# MCXN947_cm33_core0 register map
Vendor: nxp.com; File version: 1.0
CPU: CM33 r2p0, little endian, MPU, FPU, VTOR, 3 interrupt priority bits
Registers are 32-bit, read-write, reset 0x0 unless marked. A register's access mark holds for its fields unless they carry their own. Offsets are from the block's base; [hi:lo] are bit positions; {n}, {i} and the like mark numbered series; 'fields as' and 'values as' point back to an identical list.

## WUU0 — WUU
Base 0x40046000
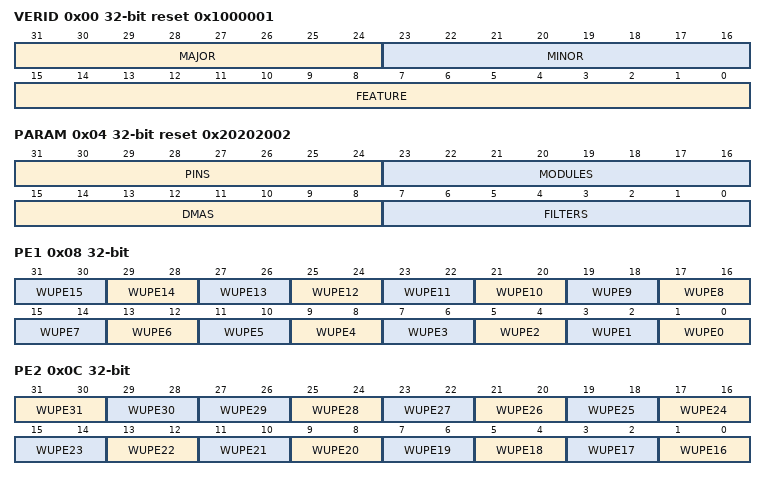
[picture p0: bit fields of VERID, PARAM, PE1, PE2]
0x00 VERID ro reset 0x1000001 — Version ID
  [31:24] MAJOR — Major Version Number
  [23:16] MINOR — Minor Version Number
  [15:0] FEATURE — Feature Specification Number
    0=STANDARD (Standard features implemented); 1=FILT_ALL_PWR (Support for DMA/Trigger generation from wake-up pins and filters enabled. Support for external pin/filter detection during all power modes enabled.)
0x04 PARAM ro reset 0x20202002 — Parameter
  [31:24] PINS — Pin Number
  [23:16] MODULES — Module Number
  [15:8] DMAS — DMA Number
  [7:0] FILTERS — Filter Number
0x08 PE1 — Pin Enable 1
  [all] fields
    0=DISABLE; 1=EN_RISE_HI (Enable (detect on rising edge or high level)); 2=EN_FALL_LO (Enable (detect on falling edge or low level)); 3=EN_ANY (Enable (detect on any edge))
  [2n+1:2n] WUPE{n} (n=0..15) — Wake-up Pin Enable for WUU_Pn
0x0C PE2 — Pin Enable 2
  [31:30] WUPE31 — Reserved
    0=DISABLE (Not supported); 1=EN_RISE_HI (Not supported); 2=EN_FALL_LO (Not supported); 3=EN_ANY (Not supported)
  [29:28] WUPE30 — Reserved
    values as WUPE31
  [2n-31:2n-32] WUPE{n} (n=16..29) — Wake-up Pin Enable for WUU_Pn
    values as the fields of PE1
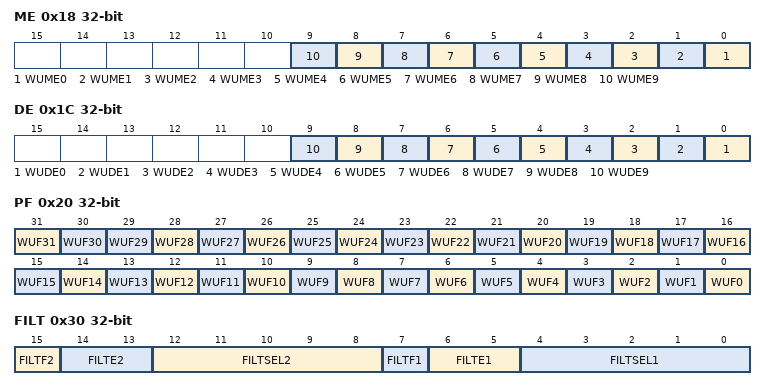
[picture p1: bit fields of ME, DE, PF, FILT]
0x18 ME — Module Interrupt Enable
  [all] fields
    0=DISABLE (Disables); 1=ENABLE (Enables)
  [n] WUME{n} (n=0..9) — Module Interrupt Wake-up Enable for Module n
0x1C DE — Module DMA/Trigger Enable
  [all] fields
    0=DISABLE (Disables); 1=ENABLE (Enables)
  [n] WUDE{n} (n=0..9) — DMA/Trigger Wake-up Enable for Module n
0x20 PF write-1-clears — Pin Flag
  [31] WUF31 write-1-clears — Reserved
    0=NO_FLAG (Not supported); 1=FLAG (Not supported)
  [30] WUF30 write-1-clears — Reserved
    0=NO_FLAG (Not supported); 1=FLAG (Not supported)
  [n] WUF{n} write-1-clears (n=0..29) — Wake-up Flag for WUU_Pn
    0=NO_FLAG; 1=FLAG (Yes)
0x30 FILT — Pin Filter
  [15] FILTF2 write-1-clears — Filter 2 Flag
    0=NO_FLAG; 1=FLAG (Yes)
  [14:13] FILTE2 — Filter 2 Enable
    0=DISABLE; 1=EN_RISE_HI (Enable (Detect on rising edge or high level)); 2=EN_FALL_LO (Enable (Detect on falling edge or low level)); 3=EN_ANY (Enable (Detect on any edge))
  [12:8] FILTSEL2 — Filter 2 Pin Select
  [7] FILTF1 write-1-clears — Filter 1 Flag
    0=NO_FLAG; 1=FLAG (Yes)
  [6:5] FILTE1 — Filter 1 Enable
    values as FILTE2
  [4:0] FILTSEL1 — Filter 1 Pin Select
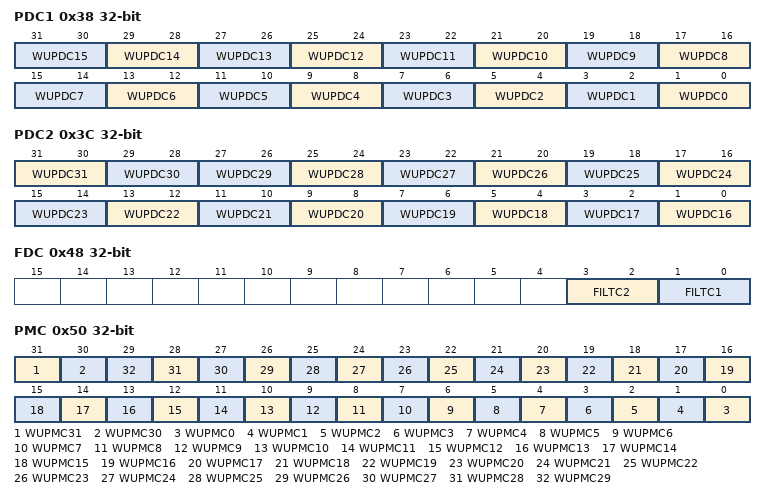
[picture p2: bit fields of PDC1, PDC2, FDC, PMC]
0x38 PDC1 — Pin DMA/Trigger Configuration 1
  [all] fields
    0=INTERRUPT; 1=DMA_REQ (DMA request); 2=TRIGGER (Trigger event)
  [2n+1:2n] WUPDC{n} (n=0..15) — Wake-up Pin Configuration for WUU_Pn
0x3C PDC2 — Pin DMA/Trigger Configuration 2
  [31:30] WUPDC31 — Reserved
    0=INTERRUPT (Not supported); 1=DMA_REQ (Not supported); 2=TRIGGER (Not supported)
  [29:28] WUPDC30 — Reserved
    values as WUPDC31
  [2n-31:2n-32] WUPDC{n} (n=16..29) — Wake-up Pin Configuration for WUU_Pn
    values as the fields of PDC1
0x48 FDC — Pin Filter DMA/Trigger Configuration
  [3:2] FILTC2 — Filter Configuration for FILTn
    values as the fields of PDC1
  [1:0] FILTC1 — Filter Configuration for FILTn
    values as the fields of PDC1
0x50 PMC — Pin Mode Configuration
  [31] WUPMC31 — Reserved
    0=LOW_PWR_ONLY (Not supported); 1=ANY_PWR (Not supported)
  [30] WUPMC30 — Reserved
    0=LOW_PWR_ONLY (Not supported); 1=ANY_PWR (Not supported)
  [n] WUPMC{n} (n=0..29) — Wake-up Pin Mode Configuration for WUU_Pn
    0=LOW_PWR_ONLY (Active only during a low-leakage mode. You can modify the corresponding fields within Pin Enable (PEn) or Pin DMA/Trigger Configuration (PDCn).); 1=ANY_PWR (Active during all power modes. Do not modify the corresponding fields within Pin Enable (PEn) or Pin DMA/Trigger Configuration (PDCn).)
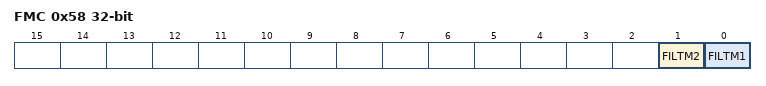
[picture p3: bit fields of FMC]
0x58 FMC — Pin Filter Mode Configuration
  [1] FILTM2 — Filter Mode for FILTn
    0=LOW_PWR_ONLY (Active only during Power Down/Deep Power Down mode); 1=ANY_PWR (Active during all power modes)
  [0] FILTM1 — Filter Mode for FILTn
    values as FILTM2
